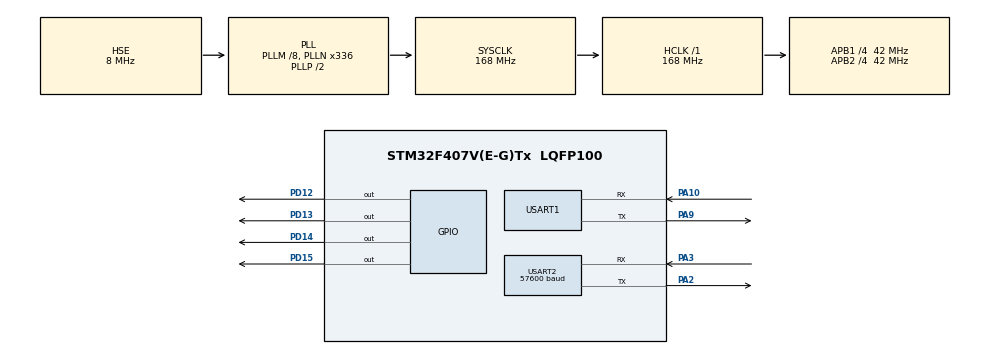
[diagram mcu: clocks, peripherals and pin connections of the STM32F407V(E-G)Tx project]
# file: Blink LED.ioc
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Dma.Request0=USART2_RX
Dma.Request1=USART2_TX
Dma.Request2=USART1_RX
Dma.Request3=USART1_TX
Dma.USART1_RX.2.Direction=DMA_PERIPH_TO_MEMORY
Dma.USART1_RX.2.FIFOMode=DMA_FIFOMODE_DISABLE
Dma.USART1_RX.2.Instance=DMA2_Stream2
Dma.USART1_RX.2.MemDataAlignment=DMA_MDATAALIGN_BYTE
Dma.USART1_RX.2.MemInc=DMA_MINC_ENABLE
Dma.USART1_RX.2.Mode=DMA_CIRCULAR
Dma.USART1_RX.2.PeriphDataAlignment=DMA_PDATAALIGN_BYTE
Dma.USART1_RX.2.PeriphInc=DMA_PINC_DISABLE
Dma.USART1_RX.2.Priority=DMA_PRIORITY_HIGH
Dma.USART1_TX.3.Direction=DMA_MEMORY_TO_PERIPH
Dma.USART1_TX.3.FIFOMode=DMA_FIFOMODE_DISABLE
Dma.USART1_TX.3.Instance=DMA2_Stream7
Dma.USART1_TX.3.MemDataAlignment=DMA_MDATAALIGN_BYTE
Dma.USART1_TX.3.MemInc=DMA_MINC_ENABLE
Dma.USART1_TX.3.Mode=DMA_NORMAL
Dma.USART1_TX.3.PeriphDataAlignment=DMA_PDATAALIGN_BYTE
Dma.USART1_TX.3.PeriphInc=DMA_PINC_DISABLE
Dma.USART1_TX.3.Priority=DMA_PRIORITY_HIGH
Dma.USART2_RX.0.Direction=DMA_PERIPH_TO_MEMORY
Dma.USART2_RX.0.FIFOMode=DMA_FIFOMODE_DISABLE
Dma.USART2_RX.0.Instance=DMA1_Stream5
Dma.USART2_RX.0.MemDataAlignment=DMA_MDATAALIGN_BYTE
Dma.USART2_RX.0.MemInc=DMA_MINC_ENABLE
Dma.USART2_RX.0.Mode=DMA_CIRCULAR
Dma.USART2_RX.0.PeriphDataAlignment=DMA_PDATAALIGN_BYTE
Dma.USART2_RX.0.PeriphInc=DMA_PINC_DISABLE
Dma.USART2_RX.0.Priority=DMA_PRIORITY_HIGH
Dma.USART2_TX.1.Direction=DMA_MEMORY_TO_PERIPH
Dma.USART2_TX.1.FIFOMode=DMA_FIFOMODE_DISABLE
Dma.USART2_TX.1.Instance=DMA1_Stream6
Dma.USART2_TX.1.MemDataAlignment=DMA_MDATAALIGN_BYTE
Dma.USART2_TX.1.MemInc=DMA_MINC_ENABLE
Dma.USART2_TX.1.Mode=DMA_NORMAL
Dma.USART2_TX.1.PeriphDataAlignment=DMA_PDATAALIGN_BYTE
Dma.USART2_TX.1.PeriphInc=DMA_PINC_DISABLE
Dma.USART2_TX.1.Priority=DMA_PRIORITY_HIGH
Mcu.Family=STM32F4
Mcu.Name=STM32F407V(E-G)Tx
Mcu.Package=LQFP100
NVIC.DMA1_Stream5_IRQn=true\:0\:0\:false\:false\:true\:false\:true
NVIC.DMA1_Stream6_IRQn=true\:0\:0\:false\:false\:true\:false\:true
NVIC.DMA2_Stream2_IRQn=true\:0\:0\:false\:false\:true\:false\:true
NVIC.DMA2_Stream7_IRQn=true\:0\:0\:false\:false\:true\:false\:true
NVIC.PriorityGroup=NVIC_PRIORITYGROUP_4
NVIC.USART1_IRQn=true\:0\:0\:false\:false\:true\:true\:true
NVIC.USART2_IRQn=true\:0\:0\:false\:false\:true\:true\:true
PA10.Mode=Asynchronous
PA10.Signal=USART1_RX
PA2.Mode=Asynchronous
PA2.Signal=USART2_TX
PA3.Mode=Asynchronous
PA3.Signal=USART2_RX
PA9.Mode=Asynchronous
PA9.Signal=USART1_TX
PD12.GPIO_ModeDefaultOutputPP=GPIO_MODE_OUTPUT_PP
PD12.GPIO_PuPd=GPIO_NOPULL
PD12.GPIO_Speed=GPIO_SPEED_FREQ_VERY_HIGH
PD12.PinState=GPIO_PIN_SET
PD12.Signal=GPIO_Output
PD13.GPIO_ModeDefaultOutputPP=GPIO_MODE_OUTPUT_PP
PD13.GPIO_PuPd=GPIO_NOPULL
PD13.GPIO_Speed=GPIO_SPEED_FREQ_VERY_HIGH
PD13.PinState=GPIO_PIN_SET
PD13.Signal=GPIO_Output
PD14.GPIO_ModeDefaultOutputPP=GPIO_MODE_OUTPUT_PP
PD14.GPIO_PuPd=GPIO_NOPULL
PD14.GPIO_Speed=GPIO_SPEED_FREQ_VERY_HIGH
PD14.PinState=GPIO_PIN_SET
PD14.Signal=GPIO_Output
PD15.GPIO_ModeDefaultOutputPP=GPIO_MODE_OUTPUT_PP
PD15.GPIO_PuPd=GPIO_NOPULL
PD15.GPIO_Speed=GPIO_SPEED_FREQ_VERY_HIGH
PD15.PinState=GPIO_PIN_SET
PD15.Signal=GPIO_Output
PH0-OSC_IN.Mode=HSE-External-Oscillator
PH0-OSC_IN.Signal=RCC_OSC_IN
PH1-OSC_OUT.Mode=HSE-External-Oscillator
PH1-OSC_OUT.Signal=RCC_OSC_OUT
ProjectManager.HeapSize=0x200
ProjectManager.StackSize=0x400
ProjectManager.TargetToolchain=STM32CubeIDE
RCC.48MHZClocksFreq_Value=84000000
RCC.AHBFreq_Value=168000000
RCC.APB1CLKDivider=RCC_HCLK_DIV4
RCC.APB1Freq_Value=42000000
RCC.APB1TimFreq_Value=84000000
RCC.APB2CLKDivider=RCC_HCLK_DIV4
RCC.APB2Freq_Value=42000000
RCC.APB2TimFreq_Value=84000000
RCC.CortexFreq_Value=168000000
RCC.HCLKFreq_Value=168000000
RCC.HSE_VALUE=8000000
RCC.HSI_VALUE=16000000
RCC.LSE_VALUE=32768
RCC.PLLM=8
RCC.PLLN=336
RCC.PLLSourceVirtual=RCC_PLLSOURCE_HSE
RCC.SYSCLKFreq_VALUE=168000000
RCC.SYSCLKSource=RCC_SYSCLKSOURCE_PLLCLK
RCC.VCOOutputFreq_Value=336000000
USART1.VirtualMode=VM_ASYNC
USART2.BaudRate=57600
USART2.VirtualMode=VM_ASYNC
board=Blink LED

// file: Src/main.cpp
/* USER CODE BEGIN Header */
/**
  ******************************************************************************
  * @file           : main.c
  * @brief          : Main program body
  ******************************************************************************
  * @attention
  *
  * <h2><center>&copy; Copyright (c) 2022 STMicroelectronics.
  * All rights reserved.</center></h2>
  *
  * This software component is licensed by ST under BSD 3-Clause license,
  * the "License"; You may not use this file except in compliance with the
  * License. You may obtain a copy of the License at:
  *                        opensource.org/licenses/BSD-3-Clause
  *
  ******************************************************************************
  */
/* USER CODE END Header */
#include "main.h"

/* USER CODE BEGIN Includes */
#include "mainpp.h"
#include <stdio.h>
/* USER CODE END Includes */

UART_HandleTypeDef huart1;
UART_HandleTypeDef huart2;
DMA_HandleTypeDef hdma_usart1_rx;
DMA_HandleTypeDef hdma_usart1_tx;
DMA_HandleTypeDef hdma_usart2_rx;
DMA_HandleTypeDef hdma_usart2_tx;

void SystemClock_Config(void);
static void MX_GPIO_Init(void);
static void MX_USART2_UART_Init(void);
static void MX_DMA_Init(void);
static void MX_USART1_UART_Init(void);

/* USER CODE BEGIN 0 */
char buff_t[20];
uint8_t countt;
/* USER CODE END 0 */

int main(void)
{

  /* MCU Configuration--------------------------------------------------------*/

  /* Reset of all peripherals, Initializes the Flash interface and the Systick. */
  HAL_Init();

  /* Configure the system clock */
  SystemClock_Config();

  /* Initialize all configured peripherals */

  MX_GPIO_Init();
  MX_DMA_Init();
  MX_USART2_UART_Init();
  MX_USART1_UART_Init();
  /* USER CODE BEGIN 2 */
  setup();
  /* USER CODE END 2 */

  /* Infinite loop */
  while (1)
  {

    /* USER CODE BEGIN 3 */
//	  countt++;
//	  HAL_GPIO_TogglePin(GPIOD, GPIO_PIN_12 | GPIO_PIN_13);
//	  sprintf(buff_t, "Hello Thong :D %d", countt);
//	  HAL_UART_Transmit_DMA(&huart2, (uint8_t *)buff_t, 20);
//	  //HAL_GPIO_TogglePin(GPIOB, LD1_Pin|LD3_Pin|LD2_Pin);
//
//	  HAL_Delay(500);
	 loop();
  }
  /* USER CODE END 3 */
}

void SystemClock_Config(void)
{
  RCC_OscInitTypeDef RCC_OscInitStruct = {0};
  RCC_ClkInitTypeDef RCC_ClkInitStruct = {0};

  /** Configure the main internal regulator output voltage
  */
  __HAL_RCC_PWR_CLK_ENABLE();
  __HAL_PWR_VOLTAGESCALING_CONFIG(PWR_REGULATOR_VOLTAGE_SCALE1);
  /** Initializes the RCC Oscillators according to the specified parameters
  * in the RCC_OscInitTypeDef structure.
  */
  RCC_OscInitStruct.OscillatorType = RCC_OSCILLATORTYPE_HSE;
  RCC_OscInitStruct.HSEState = RCC_HSE_ON;
  RCC_OscInitStruct.PLL.PLLState = RCC_PLL_ON;
  RCC_OscInitStruct.PLL.PLLSource = RCC_PLLSOURCE_HSE;
  RCC_OscInitStruct.PLL.PLLM = 8;
  RCC_OscInitStruct.PLL.PLLN = 336;
  RCC_OscInitStruct.PLL.PLLP = RCC_PLLP_DIV2;
  RCC_OscInitStruct.PLL.PLLQ = 4;
  if (HAL_RCC_OscConfig(&RCC_OscInitStruct) != HAL_OK)
  {
    Error_Handler();
  }
  /** Initializes the CPU, AHB and APB buses clocks
  */
  RCC_ClkInitStruct.ClockType = RCC_CLOCKTYPE_HCLK|RCC_CLOCKTYPE_SYSCLK
                              |RCC_CLOCKTYPE_PCLK1|RCC_CLOCKTYPE_PCLK2;
  RCC_ClkInitStruct.SYSCLKSource = RCC_SYSCLKSOURCE_PLLCLK;
  RCC_ClkInitStruct.AHBCLKDivider = RCC_SYSCLK_DIV1;
  RCC_ClkInitStruct.APB1CLKDivider = RCC_HCLK_DIV4;
  RCC_ClkInitStruct.APB2CLKDivider = RCC_HCLK_DIV4;

  if (HAL_RCC_ClockConfig(&RCC_ClkInitStruct, FLASH_LATENCY_5) != HAL_OK)
  {
    Error_Handler();
  }
}

static void MX_USART1_UART_Init(void)
{

  huart1.Instance = USART1;
  huart1.Init.BaudRate = 115200;
  huart1.Init.WordLength = UART_WORDLENGTH_8B;
  huart1.Init.StopBits = UART_STOPBITS_1;
  huart1.Init.Parity = UART_PARITY_NONE;
  huart1.Init.Mode = UART_MODE_TX_RX;
  huart1.Init.HwFlowCtl = UART_HWCONTROL_NONE;
  huart1.Init.OverSampling = UART_OVERSAMPLING_16;
  if (HAL_UART_Init(&huart1) != HAL_OK)
  {
    Error_Handler();
  }

}

static void MX_USART2_UART_Init(void)
{

  huart2.Instance = USART2;
  huart2.Init.BaudRate = 57600;
  huart2.Init.WordLength = UART_WORDLENGTH_8B;
  huart2.Init.StopBits = UART_STOPBITS_1;
  huart2.Init.Parity = UART_PARITY_NONE;
  huart2.Init.Mode = UART_MODE_TX_RX;
  huart2.Init.HwFlowCtl = UART_HWCONTROL_NONE;
  huart2.Init.OverSampling = UART_OVERSAMPLING_16;
  if (HAL_UART_Init(&huart2) != HAL_OK)
  {
    Error_Handler();
  }

}

static void MX_DMA_Init(void)
{

  /* DMA controller clock enable */
  __HAL_RCC_DMA1_CLK_ENABLE();
  __HAL_RCC_DMA2_CLK_ENABLE();

  /* DMA interrupt init */
  /* DMA1_Stream5_IRQn interrupt configuration */
  HAL_NVIC_SetPriority(DMA1_Stream5_IRQn, 0, 0);
  HAL_NVIC_EnableIRQ(DMA1_Stream5_IRQn);
  /* DMA1_Stream6_IRQn interrupt configuration */
  HAL_NVIC_SetPriority(DMA1_Stream6_IRQn, 0, 0);
  HAL_NVIC_EnableIRQ(DMA1_Stream6_IRQn);
  /* DMA2_Stream2_IRQn interrupt configuration */
  HAL_NVIC_SetPriority(DMA2_Stream2_IRQn, 0, 0);
  HAL_NVIC_EnableIRQ(DMA2_Stream2_IRQn);
  /* DMA2_Stream7_IRQn interrupt configuration */
  HAL_NVIC_SetPriority(DMA2_Stream7_IRQn, 0, 0);
  HAL_NVIC_EnableIRQ(DMA2_Stream7_IRQn);

}

static void MX_GPIO_Init(void)
{
  GPIO_InitTypeDef GPIO_InitStruct = {0};

  /* GPIO Ports Clock Enable */
  __HAL_RCC_GPIOH_CLK_ENABLE();
  __HAL_RCC_GPIOA_CLK_ENABLE();
  __HAL_RCC_GPIOD_CLK_ENABLE();

  /*Configure GPIO pin Output Level */
  HAL_GPIO_WritePin(GPIOD, GPIO_PIN_12|GPIO_PIN_13|GPIO_PIN_14|GPIO_PIN_15, GPIO_PIN_SET);

  /*Configure GPIO pins : PD12 PD13 PD14 PD15 */
  GPIO_InitStruct.Pin = GPIO_PIN_12|GPIO_PIN_13|GPIO_PIN_14|GPIO_PIN_15;
  GPIO_InitStruct.Mode = GPIO_MODE_OUTPUT_PP;
  GPIO_InitStruct.Pull = GPIO_NOPULL;
  GPIO_InitStruct.Speed = GPIO_SPEED_FREQ_VERY_HIGH;
  HAL_GPIO_Init(GPIOD, &GPIO_InitStruct);

}

void Error_Handler(void)
{
  __disable_irq();
  while (1)
  {
  }
}

/************************ (C) COPYRIGHT STMicroelectronics *****END OF FILE****/
